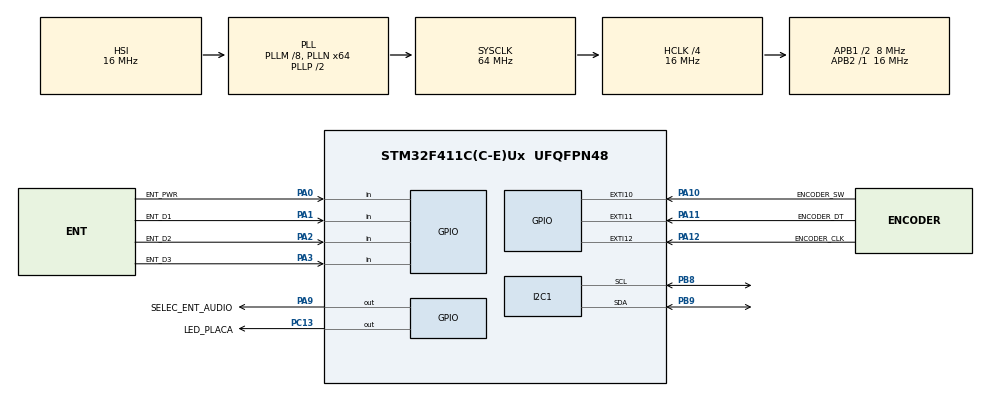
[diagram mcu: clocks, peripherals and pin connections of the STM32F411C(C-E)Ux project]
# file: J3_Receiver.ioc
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Mcu.Family=STM32F4
Mcu.Name=STM32F411C(C-E)Ux
Mcu.Package=UFQFPN48
NVIC.EXTI15_10_IRQn=true\:1\:0\:true\:false\:true\:true\:true\:true
NVIC.PriorityGroup=NVIC_PRIORITYGROUP_4
PA0-WKUP.GPIO_Label=ENT_PWR
PA0-WKUP.Signal=GPIO_Input
PA1.GPIO_Label=ENT_D1
PA1.GPIO_PuPd=GPIO_NOPULL
PA1.Signal=GPIO_Input
PA10.GPIO_Label=ENCODER_SW
PA10.GPIO_ModeDefaultEXTI=GPIO_MODE_IT_RISING
PA10.GPIO_PuPd=GPIO_PULLUP
PA10.Signal=GPXTI10
PA11.GPIO_Label=ENCODER_DT
PA11.GPIO_ModeDefaultEXTI=GPIO_MODE_IT_FALLING
PA11.GPIO_PuPd=GPIO_NOPULL
PA11.Signal=GPXTI11
PA12.GPIO_Label=ENCODER_CLK
PA12.GPIO_ModeDefaultEXTI=GPIO_MODE_IT_FALLING
PA12.GPIO_PuPd=GPIO_NOPULL
PA12.Signal=GPXTI12
PA13.Mode=JTAG_4_pins
PA13.Signal=SYS_JTMS-SWDIO
PA14.Mode=JTAG_4_pins
PA14.Signal=SYS_JTCK-SWCLK
PA15.Mode=JTAG_4_pins
PA15.Signal=SYS_JTDI
PA2.GPIO_Label=ENT_D2
PA2.Signal=GPIO_Input
PA3.GPIO_Label=ENT_D3
PA3.Signal=GPIO_Input
PA9.GPIO_Label=SELEC_ENT_AUDIO
PA9.GPIO_ModeDefaultOutputPP=GPIO_MODE_OUTPUT_OD
PA9.GPIO_PuPd=GPIO_NOPULL
PA9.GPIO_Speed=GPIO_SPEED_FREQ_LOW
PA9.PinState=GPIO_PIN_SET
PA9.Signal=GPIO_Output
PB3.Mode=JTAG_4_pins
PB3.Signal=SYS_JTDO-SWO
PB8.GPIO_Pu=GPIO_PULLUP
PB8.Mode=I2C
PB8.Signal=I2C1_SCL
PB9.GPIO_Pu=GPIO_PULLUP
PB9.Mode=I2C
PB9.Signal=I2C1_SDA
PC13-ANTI_TAMP.GPIO_Label=LED_PLACA
PC13-ANTI_TAMP.Signal=GPIO_Output
PC14-OSC32_IN.Mode=LSE-External-Oscillator
PC14-OSC32_IN.Signal=RCC_OSC32_IN
PC15-OSC32_OUT.Mode=LSE-External-Oscillator
PC15-OSC32_OUT.Signal=RCC_OSC32_OUT
PH0\ -\ OSC_IN.Mode=HSE-External-Oscillator
PH0\ -\ OSC_IN.Signal=RCC_OSC_IN
PH1\ -\ OSC_OUT.Mode=HSE-External-Oscillator
PH1\ -\ OSC_OUT.Signal=RCC_OSC_OUT
ProjectManager.HeapSize=0x200
ProjectManager.StackSize=0x400
ProjectManager.TargetToolchain=STM32CubeIDE
RCC.48MHZClocksFreq_Value=32000000
RCC.AHBCLKDivider=RCC_SYSCLK_DIV4
RCC.AHBFreq_Value=16000000
RCC.APB1CLKDivider=RCC_HCLK_DIV2
RCC.APB1Freq_Value=8000000
RCC.APB1TimFreq_Value=16000000
RCC.APB2Freq_Value=16000000
RCC.APB2TimFreq_Value=16000000
RCC.CortexFreq_Value=16000000
RCC.DATA_CACHE_ENABLE=1
RCC.HCLKFreq_Value=16000000
RCC.HSE_VALUE=25000000
RCC.HSI_VALUE=16000000
RCC.PLLM=8
RCC.PLLN=64
RCC.SYSCLKFreq_VALUE=64000000
RCC.SYSCLKSource=RCC_SYSCLKSOURCE_PLLCLK
RCC.VCOOutputFreq_Value=128000000
board=custom

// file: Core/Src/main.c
/* USER CODE BEGIN Header */
/**
  ******************************************************************************
  * @file           : main.c
  * @brief          : Main program body
  ******************************************************************************
  * @attention
  *
  * Copyright (c) 2023 STMicroelectronics.
  * All rights reserved.
  *
  * This software is licensed under terms that can be found in the LICENSE file
  * in the root directory of this software component.
  * If no LICENSE file comes with this software, it is provided AS-IS.
  *
  ******************************************************************************
  */
/* USER CODE END Header */
#include "main.h"
#include "i2c.h"
#include "gpio.h"

/* USER CODE BEGIN Includes */
#include "usr/main_J3_Receiver.h"
/* USER CODE END Includes */

void SystemClock_Config(void);

int main(void)
{

  /* MCU Configuration--------------------------------------------------------*/

  /* Reset of all peripherals, Initializes the Flash interface and the Systick. */
  HAL_Init();

  /* Configure the system clock */
  SystemClock_Config();

  /* Initialize all configured peripherals */
  MX_GPIO_Init();
  MX_I2C1_Init();

  /* Infinite loop */
  while (1)
  {

    /* USER CODE BEGIN 3 */
	  main_j3_receiver();
  }
  /* USER CODE END 3 */
}

void SystemClock_Config(void)
{
  RCC_OscInitTypeDef RCC_OscInitStruct = {0};
  RCC_ClkInitTypeDef RCC_ClkInitStruct = {0};

  /** Configure the main internal regulator output voltage
  */
  __HAL_RCC_PWR_CLK_ENABLE();
  __HAL_PWR_VOLTAGESCALING_CONFIG(PWR_REGULATOR_VOLTAGE_SCALE1);

  /** Initializes the RCC Oscillators according to the specified parameters
  * in the RCC_OscInitTypeDef structure.
  */
  RCC_OscInitStruct.OscillatorType = RCC_OSCILLATORTYPE_HSI;
  RCC_OscInitStruct.HSIState = RCC_HSI_ON;
  RCC_OscInitStruct.HSICalibrationValue = RCC_HSICALIBRATION_DEFAULT;
  RCC_OscInitStruct.PLL.PLLState = RCC_PLL_ON;
  RCC_OscInitStruct.PLL.PLLSource = RCC_PLLSOURCE_HSI;
  RCC_OscInitStruct.PLL.PLLM = 8;
  RCC_OscInitStruct.PLL.PLLN = 64;
  RCC_OscInitStruct.PLL.PLLP = RCC_PLLP_DIV2;
  RCC_OscInitStruct.PLL.PLLQ = 4;
  if (HAL_RCC_OscConfig(&RCC_OscInitStruct) != HAL_OK)
  {
    Error_Handler();
  }

  /** Initializes the CPU, AHB and APB buses clocks
  */
  RCC_ClkInitStruct.ClockType = RCC_CLOCKTYPE_HCLK|RCC_CLOCKTYPE_SYSCLK
                              |RCC_CLOCKTYPE_PCLK1|RCC_CLOCKTYPE_PCLK2;
  RCC_ClkInitStruct.SYSCLKSource = RCC_SYSCLKSOURCE_PLLCLK;
  RCC_ClkInitStruct.AHBCLKDivider = RCC_SYSCLK_DIV4;
  RCC_ClkInitStruct.APB1CLKDivider = RCC_HCLK_DIV2;
  RCC_ClkInitStruct.APB2CLKDivider = RCC_HCLK_DIV1;

  if (HAL_RCC_ClockConfig(&RCC_ClkInitStruct, FLASH_LATENCY_0) != HAL_OK)
  {
    Error_Handler();
  }
}

void Error_Handler(void)
{
  __disable_irq();
  while (1)
  {
  }
}
